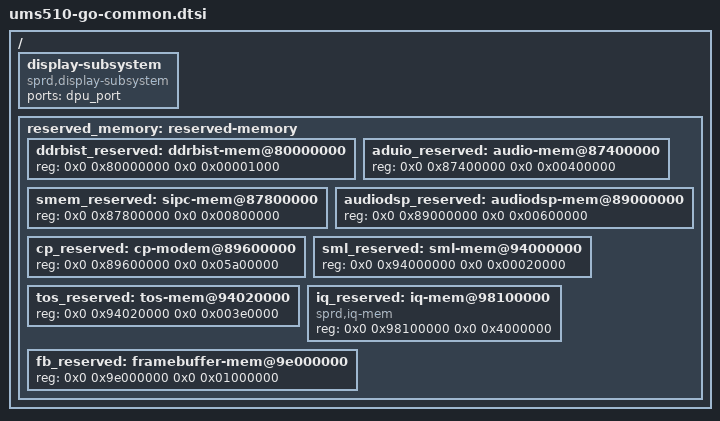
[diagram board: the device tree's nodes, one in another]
// SPDX-License-Identifier: (GPL-2.0+ OR MIT)
/*
 * Spreadtrum Sharkl5 platform androig go common dtsi file
 *
 * Copyright (C) 2018, Spreadtrum Communications Inc.
 */

/ {
	display-subsystem {
		compatible = "sprd,display-subsystem";
		ports = <&dpu_port>;
	};

	reserved_memory: reserved-memory {
		#address-cells = <2>;
		#size-cells = <2>;
		ranges;

		ddrbist_reserved: ddrbist-mem@80000000{
			reg = <0x0 0x80000000 0x0 0x00001000>;
		};

		aduio_reserved: audio-mem@87400000{
			reg = <0x0 0x87400000 0x0 0x00400000>;
		};

		smem_reserved: sipc-mem@87800000{
			reg = <0x0 0x87800000 0x0 0x00800000>;
		};

		audiodsp_reserved: audiodsp-mem@89000000 {
			reg = <0x0 0x89000000 0x0 0x00600000>;
		};

		cp_reserved: cp-modem@89600000 {
			reg = <0x0 0x89600000 0x0 0x05a00000>;
		};

		/* must be 64M aligned */
		sml_reserved: sml-mem@94000000{
			reg = <0x0 0x94000000 0x0 0x00020000>;
		};

		tos_reserved: tos-mem@94020000{
			reg = <0x0 0x94020000 0x0 0x003e0000>;
		};

		/* Only used for iq, will be removed in normal mode by uboot */
		iq_reserved: iq-mem@98100000{
			compatible = "sprd,iq-mem";
			reg = <0x0 0x98100000 0x0 0x4000000>;
		};

		fb_reserved: framebuffer-mem@9e000000{
			reg = <0x0 0x9e000000 0x0 0x01000000>;
		};
	};
};

